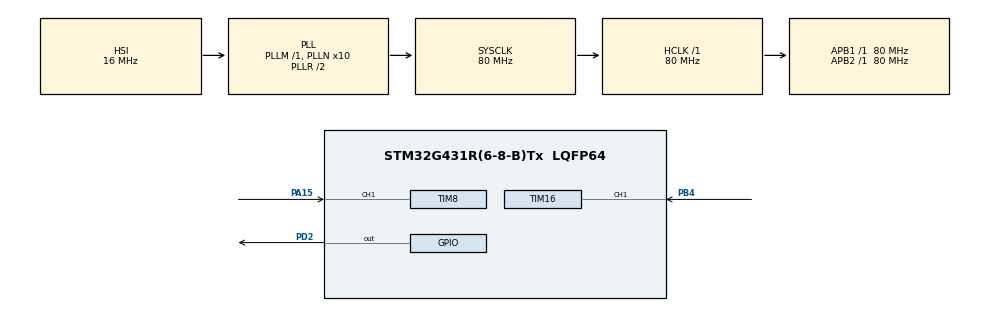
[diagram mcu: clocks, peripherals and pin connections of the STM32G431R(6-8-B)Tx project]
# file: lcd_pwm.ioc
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Mcu.Family=STM32G4
Mcu.Name=STM32G431R(6-8-B)Tx
Mcu.Package=LQFP64
NVIC.PriorityGroup=NVIC_PRIORITYGROUP_4
NVIC.TIM1_UP_TIM16_IRQn=true\:0\:0\:false\:false\:true\:true\:true
NVIC.TIM8_BRK_IRQn=true\:0\:0\:false\:false\:true\:true\:true
NVIC.TIM8_CC_IRQn=true\:0\:0\:false\:false\:true\:true\:true
NVIC.TIM8_TRG_COM_IRQn=true\:0\:0\:false\:false\:true\:true\:true
NVIC.TIM8_UP_IRQn=true\:0\:0\:false\:false\:true\:true\:true
PA13.Mode=Serial_Wire
PA13.Signal=SYS_JTMS-SWDIO
PA14.Mode=Serial_Wire
PA14.Signal=SYS_JTCK-SWCLK
PA15.Signal=S_TIM8_CH1
PB4.Signal=S_TIM16_CH1
PD2.Signal=GPIO_Output
ProjectManager.HeapSize=0x200
ProjectManager.StackSize=0x400
ProjectManager.TargetToolchain=MDK-ARM V5.32
RCC.ADC12Freq_Value=80000000
RCC.AHBFreq_Value=80000000
RCC.APB1Freq_Value=80000000
RCC.APB1TimFreq_Value=80000000
RCC.APB2Freq_Value=80000000
RCC.APB2TimFreq_Value=80000000
RCC.CortexFreq_Value=80000000
RCC.EXTERNAL_CLOCK_VALUE=12288000
RCC.HCLKFreq_Value=80000000
RCC.HSE_VALUE=8000000
RCC.HSI48_VALUE=48000000
RCC.HSI_VALUE=16000000
RCC.LSE_VALUE=32768
RCC.PLLN=10
RCC.SYSCLKFreq_VALUE=80000000
RCC.SYSCLKSource=RCC_SYSCLKSOURCE_PLLCLK
RCC.USBFreq_Value=80000000
RCC.VCOOutputFreq_Value=160000000
SH.S_TIM16_CH1.0=TIM16_CH1,Input_Capture1_from_TI1
SH.S_TIM8_CH1.0=TIM8_CH1,Input_Capture1_from_TI1
TIM16.Channel=TIM_CHANNEL_1
TIM16.Prescaler=80 - 1
TIM8.Channel-Input_Capture1_from_TI1=TIM_CHANNEL_1
TIM8.Prescaler=80 -1
VP_SYS_VS_DBSignals.Mode=DisableDeadBatterySignals
VP_TIM16_VS_ClockSourceINT.Mode=Enable_Timer
board=custom

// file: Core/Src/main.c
/* USER CODE BEGIN Header */
/**
  ******************************************************************************
  * @file           : main.c
  * @brief          : Main program body
  ******************************************************************************
  * @attention
  *
  * <h2><center>&copy; Copyright (c) 2025 STMicroelectronics.
  * All rights reserved.</center></h2>
  *
  * This software component is licensed by ST under BSD 3-Clause license,
  * the "License"; You may not use this file except in compliance with the
  * License. You may obtain a copy of the License at:
  *                        opensource.org/licenses/BSD-3-Clause
  *
  ******************************************************************************
  */
/* USER CODE END Header */
#include "main.h"
#include "tim.h"
#include "gpio.h"

/* USER CODE BEGIN Includes */
#include "lcd.h"
#include <stdio.h>
/* USER CODE END Includes */

void SystemClock_Config(void);

/* USER CODE BEGIN 0 */
static void lcd_init()
{
    LCD_Init();
    LCD_Clear(Black);
    LCD_SetBackColor(Black);
    LCD_SetTextColor(White);
}

char buf[20];
static void lcd_test_disp()
{
    snprintf(buf, 20, "     Hello, LCD!");
    LCD_DisplayStringLine(Line0, (u8*)buf);
}

long long r39_f, r40_f;
static void lcd_show_runtime_freq()
{
    snprintf(buf, 20, "   Test   ");
    LCD_DisplayStringLine(Line0, (u8*)buf);
    snprintf(buf, 20, " freq1: %lld   ", r39_f);
    LCD_DisplayStringLine(Line1, (u8*)buf);
    snprintf(buf, 20, " freq2: %lld   ", r40_f);
    LCD_DisplayStringLine(Line2, (u8*)buf);
}

void HAL_TIM_IC_CaptureCallback(TIM_HandleTypeDef *htim)
{
    uint32_t cap;
    if(htim == &htim16)
    {
        // R39
        cap = HAL_TIM_ReadCapturedValue(&htim16, TIM_CHANNEL_1);
        htim16.Instance->CNT = 0;
        r39_f = 80000000UL / (80 * cap);
    }else if(htim == &htim8){
        cap = HAL_TIM_ReadCapturedValue(&htim8, TIM_CHANNEL_1);
        htim8.Instance->CNT = 0;
        r40_f = 80000000UL / (80 * cap);
    }
}

/* USER CODE END 0 */

int main(void)
{

  /* MCU Configuration--------------------------------------------------------*/

  /* Reset of all peripherals, Initializes the Flash interface and the Systick. */
  HAL_Init();

  /* Configure the system clock */
  SystemClock_Config();

  /* Initialize all configured peripherals */
  MX_GPIO_Init();
  MX_TIM8_Init();
  MX_TIM16_Init();
  /* USER CODE BEGIN 2 */
  lcd_init();
  init_led();
  // lcd_test_disp();

  HAL_TIM_IC_Start_IT(&htim16, TIM_CHANNEL_1);
  HAL_TIM_IC_Start_IT(&htim8, TIM_CHANNEL_1);

  /* USER CODE END 2 */

  /* Infinite loop */
  while (1)
  {

    /* USER CODE BEGIN 3 */
      toggle_led(GPIO_PIN_8);
      lcd_show_runtime_freq();
      HAL_Delay(500);
  }
  /* USER CODE END 3 */
}

void SystemClock_Config(void)
{
  RCC_OscInitTypeDef RCC_OscInitStruct = {0};
  RCC_ClkInitTypeDef RCC_ClkInitStruct = {0};

  /** Configure the main internal regulator output voltage
  */
  HAL_PWREx_ControlVoltageScaling(PWR_REGULATOR_VOLTAGE_SCALE1);
  /** Initializes the RCC Oscillators according to the specified parameters
  * in the RCC_OscInitTypeDef structure.
  */
  RCC_OscInitStruct.OscillatorType = RCC_OSCILLATORTYPE_HSI;
  RCC_OscInitStruct.HSIState = RCC_HSI_ON;
  RCC_OscInitStruct.HSICalibrationValue = RCC_HSICALIBRATION_DEFAULT;
  RCC_OscInitStruct.PLL.PLLState = RCC_PLL_ON;
  RCC_OscInitStruct.PLL.PLLSource = RCC_PLLSOURCE_HSI;
  RCC_OscInitStruct.PLL.PLLM = RCC_PLLM_DIV1;
  RCC_OscInitStruct.PLL.PLLN = 10;
  RCC_OscInitStruct.PLL.PLLP = RCC_PLLP_DIV2;
  RCC_OscInitStruct.PLL.PLLQ = RCC_PLLQ_DIV2;
  RCC_OscInitStruct.PLL.PLLR = RCC_PLLR_DIV2;
  if (HAL_RCC_OscConfig(&RCC_OscInitStruct) != HAL_OK)
  {
    Error_Handler();
  }
  /** Initializes the CPU, AHB and APB buses clocks
  */
  RCC_ClkInitStruct.ClockType = RCC_CLOCKTYPE_HCLK|RCC_CLOCKTYPE_SYSCLK
                              |RCC_CLOCKTYPE_PCLK1|RCC_CLOCKTYPE_PCLK2;
  RCC_ClkInitStruct.SYSCLKSource = RCC_SYSCLKSOURCE_PLLCLK;
  RCC_ClkInitStruct.AHBCLKDivider = RCC_SYSCLK_DIV1;
  RCC_ClkInitStruct.APB1CLKDivider = RCC_HCLK_DIV1;
  RCC_ClkInitStruct.APB2CLKDivider = RCC_HCLK_DIV1;

  if (HAL_RCC_ClockConfig(&RCC_ClkInitStruct, FLASH_LATENCY_2) != HAL_OK)
  {
    Error_Handler();
  }
}

void Error_Handler(void)
{
  __disable_irq();
  while (1)
  {
  }
}

/************************ (C) COPYRIGHT STMicroelectronics *****END OF FILE****/
